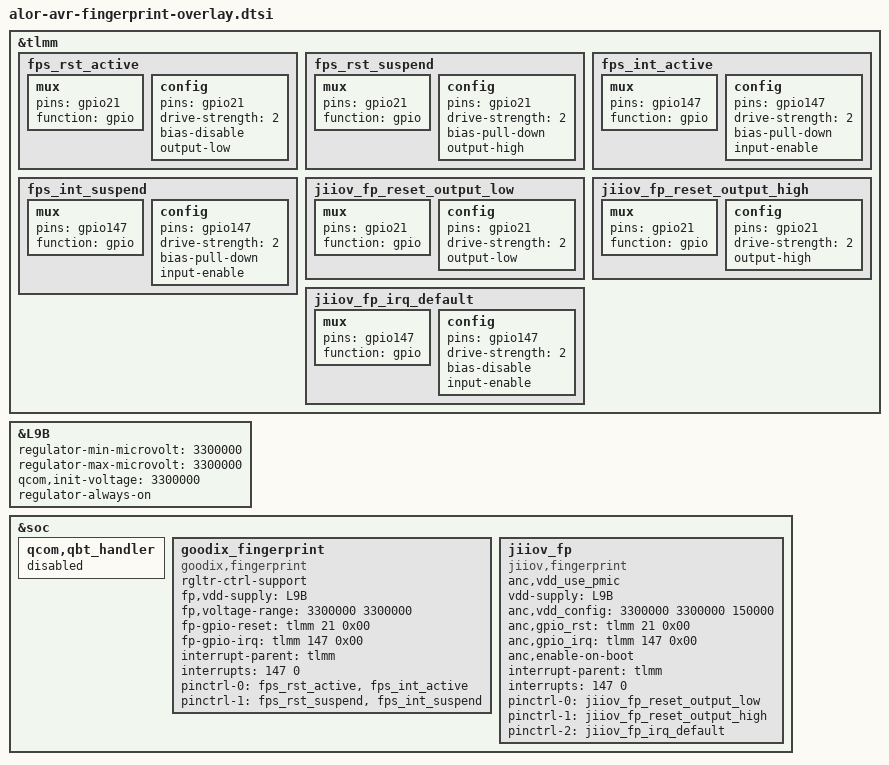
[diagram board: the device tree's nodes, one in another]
/*
 * Copyright (c) 2025 Motorola Mobility LLC.
 * All Rights Reserved.
 */

#include <dt-bindings/regulator/qcom,rpmh-regulator-levels.h>

&tlmm {

	fps_rst_active: fps_rst_active {
		/* active */
		mux {
			pins = "gpio21";
			function = "gpio";
		};
		config {
			pins = "gpio21";
			drive-strength = <2>; /* 2 MA */
			bias-disable;
			output-low;
		};
	};

	fps_rst_suspend: fps_rst_suspend {
		/* sleep */
		mux {
			pins = "gpio21";
			function = "gpio";
		};
		config {
			pins = "gpio21";
			drive-strength = <2>; /* 2 MA */
			bias-pull-down;
			output-high;
		};
	};

	fps_int_active: fps_int_active {
		/* active */
		mux {
			pins = "gpio147";
			function = "gpio";
		};
		config {
			pins = "gpio147";
			drive-strength = <2>; /* 2 MA */
			bias-pull-down;
			input-enable;
		};
	};

	fps_int_suspend: fps_int_suspend {
		/* sleep */
		mux {
			pins = "gpio147";
			function = "gpio";
		};
		config {
			pins = "gpio147";
			drive-strength = <2>; /* 2 MA */
			bias-pull-down;
			input-enable;
		};
	};

	jiiov_fp_reset_output_low: jiiov_fp_reset_output_low {
		/* active */
		mux {
			pins = "gpio21";
			function = "gpio";
		};
		config {
			pins = "gpio21";
			drive-strength = <2>; /* 2 MA */
			output-low;
		};
	};

	jiiov_fp_reset_output_high: jiiov_fp_reset_output_high {
		/* sleep */
		mux {
			pins = "gpio21";
			function = "gpio";
		};
		config {
			pins = "gpio21";
			drive-strength = <2>; /* 2 MA */
			output-high;
		};
	};

	jiiov_fp_irq_default: jiiov_fp_irq_default {
		mux {
			pins = "gpio147";
			function = "gpio";
		};
		config {
			pins = "gpio147";
			drive-strength = <2>; /* 2 MA */
			bias-disable;
			input-enable;
		};
	};

};

&L9B {
	regulator-min-microvolt = <3300000>;
	regulator-max-microvolt = <3300000>;
	qcom,init-voltage = <3300000>;
	regulator-always-on;
	status = "ok";
};

&soc {
	qcom,qbt_handler {
		status = "disabled";
	};

	goodix_fingerprint {
		compatible = "goodix,fingerprint";
		status = "ok";
		rgltr-ctrl-support;
		fp,vdd-supply = <&L9B>;
		fp,voltage-range = <3300000 3300000>;
		fp-gpio-reset = <&tlmm 21 0x00>;
		fp-gpio-irq = <&tlmm 147 0x00>;
		interrupt-parent = <&tlmm>;
		interrupts = <147 0>;
		pinctrl-names = "default", "suspend";
		pinctrl-0 = <&fps_rst_active &fps_int_active>;
		pinctrl-1 = <&fps_rst_suspend &fps_int_suspend>;
	};

	jiiov_fp {
		compatible = "jiiov,fingerprint";
		status = "ok";
		anc,vdd_use_pmic;
		vdd-supply = <&L9B>;
		anc,vdd_config = <3300000 3300000 150000>;
		anc,gpio_rst = <&tlmm 21 0x00>;
		anc,gpio_irq = <&tlmm 147 0x00>;
		anc,enable-on-boot;
		interrupt-parent = <&tlmm>;
		interrupts = <147 0>;
		pinctrl-names = "anc_reset_low", "anc_reset_high", "anc_irq_default";
		pinctrl-0 = <&jiiov_fp_reset_output_low>;
		pinctrl-1 = <&jiiov_fp_reset_output_high>;
		pinctrl-2 = <&jiiov_fp_irq_default>;
	};
};
